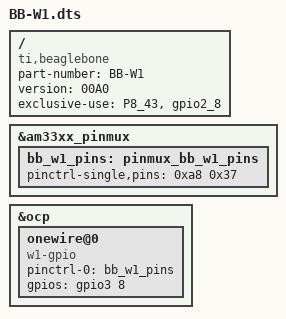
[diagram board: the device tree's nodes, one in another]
/*
* Copyright (C) 2012 Texas Instruments Incorporated - http://www.ti.com/
*
* This program is free software; you can redistribute it and/or modify
* it under the terms of the GNU General Public License version 2 as
* published by the Free Software Foundation.
* 
* Modified  by Russell Senior from the weather cape's DTS file.
* Minor formatting by C W Rose.
*/
/dts-v1/;
/plugin/;
 
/ {
    compatible = "ti,beaglebone", "ti,beaglebone-black";
    part-number = "BB-W1";
    version = "00A0";
 
	exclusive-use =
		/* the pin header uses */
		"P8_43",
		/* the hardware IP uses */
		"gpio2_8";

    fragment@0 {
        target = <&am33xx_pinmux>;
        __overlay__ {
             bb_w1_pins: pinmux_bb_w1_pins {
                 pinctrl-single,pins =  <0xa8 0x37 >;
             };
        };
    };
 
    fragment@1 {
        target = <&ocp>;
        __overlay__ {
            onewire@0 {
                status          = "okay";
                compatible      = "w1-gpio";
                pinctrl-names   = "default";
                pinctrl-0       = <&bb_w1_pins>;
 
                gpios = <&gpio3 8 0>;
            };
        };
    };
};

